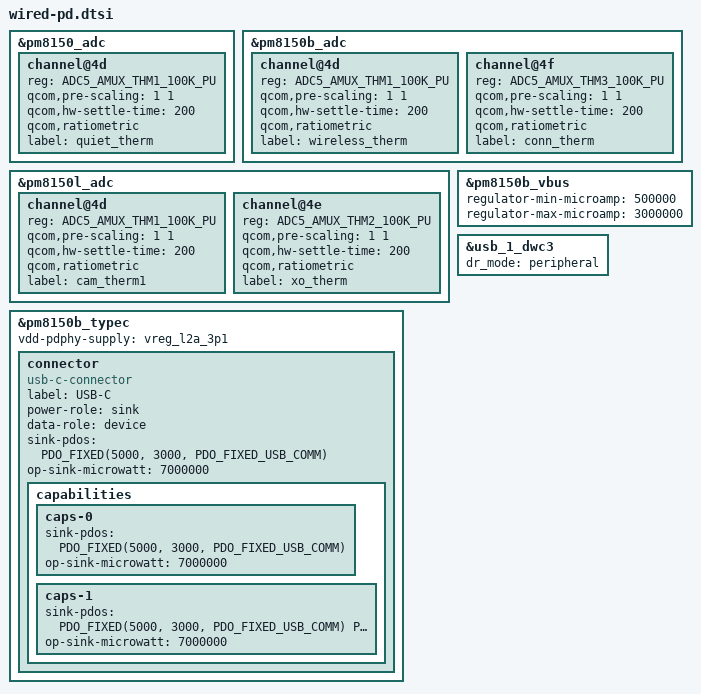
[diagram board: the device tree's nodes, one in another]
// SPDX-License-Identifier: GPL-2.0-only
/* Wired fixed PD only; from the pinned board-source snapshot. */
#include <dt-bindings/usb/pd.h>
/* Fixed LOS Umi ADC wiring. Conversion/scale is recorded during device L3. */
&pm8150_adc {
	channel@4d {
		reg = <ADC5_AMUX_THM1_100K_PU>;
		qcom,pre-scaling = <1 1>;
		qcom,hw-settle-time = <200>;
		qcom,ratiometric;
		label = "quiet_therm";
	};
};

&pm8150b_adc {
	channel@4d {
		reg = <ADC5_AMUX_THM1_100K_PU>;
		qcom,pre-scaling = <1 1>;
		qcom,hw-settle-time = <200>;
		qcom,ratiometric;
		label = "wireless_therm";
	};
	channel@4f {
		reg = <ADC5_AMUX_THM3_100K_PU>;
		qcom,pre-scaling = <1 1>;
		qcom,hw-settle-time = <200>;
		qcom,ratiometric;
		label = "conn_therm";
	};
};

&pm8150l_adc {
	channel@4d {
		reg = <ADC5_AMUX_THM1_100K_PU>;
		qcom,pre-scaling = <1 1>;
		qcom,hw-settle-time = <200>;
		qcom,ratiometric;
		label = "cam_therm1";
	};
	channel@4e {
		reg = <ADC5_AMUX_THM2_100K_PU>;
		qcom,pre-scaling = <1 1>;
		qcom,hw-settle-time = <200>;
		qcom,ratiometric;
		label = "xo_therm";
	};
};

&pm8150b_typec {
	/* Both pinned Umi mainline trees use PM8150 L2 for the PD PHY. */
	vdd-pdphy-supply = <&vreg_l2a_3p1>;
	status = "okay";

	connector {
		/delete-property/ source-pdos;
		/delete-property/ self-powered;
		compatible = "usb-c-connector";
		label = "USB-C";
		power-role = "sink";
		data-role = "device";
		/* Fixed fallback and LOS Umi USB input ceiling are 5 V / 3 A.
		 * PPS ceiling follows the source policy; runtime caps at 9.5 V.
		 */
		sink-pdos = <PDO_FIXED(5000, 3000, PDO_FIXED_USB_COMM)>;
		/* Software operating floor: existing 7 V bus floor x 1 A PPS
		 * programmable-current region; permits 10 W finishing requests.
		 */
		op-sink-microwatt = <7000000>;
		/* Standard selectable PD profiles. Attach always starts at 5 V;
		 * SMB5 prepares its input and FSW before selecting the 9 V profile.
		 */
		capabilities {
			caps-0 {
				sink-pdos = <PDO_FIXED(5000, 3000, PDO_FIXED_USB_COMM)>;
				op-sink-microwatt = <7000000>;
			};
			caps-1 {
				sink-pdos = <PDO_FIXED(5000, 3000, PDO_FIXED_USB_COMM)
					     PDO_FIXED(9000, 3000, 0)>;
				op-sink-microwatt = <7000000>;
			};
		};
	};
};

/* TCPM's required VBUS provider. This is the SOURCE/OTG boost regulator,
 * not the incoming USB path or a PPS voltage request. Type-C remains sink-only;
 * never mark this regulator boot-on/always-on.
 * Limits agree in both pinned Umi mainline trees (see NOTICE.md).
 */
&pm8150b_vbus {
	regulator-min-microamp = <500000>;
	regulator-max-microamp = <3000000>;
	status = "okay";
};


&usb_1_dwc3 { dr_mode = "peripheral"; };
